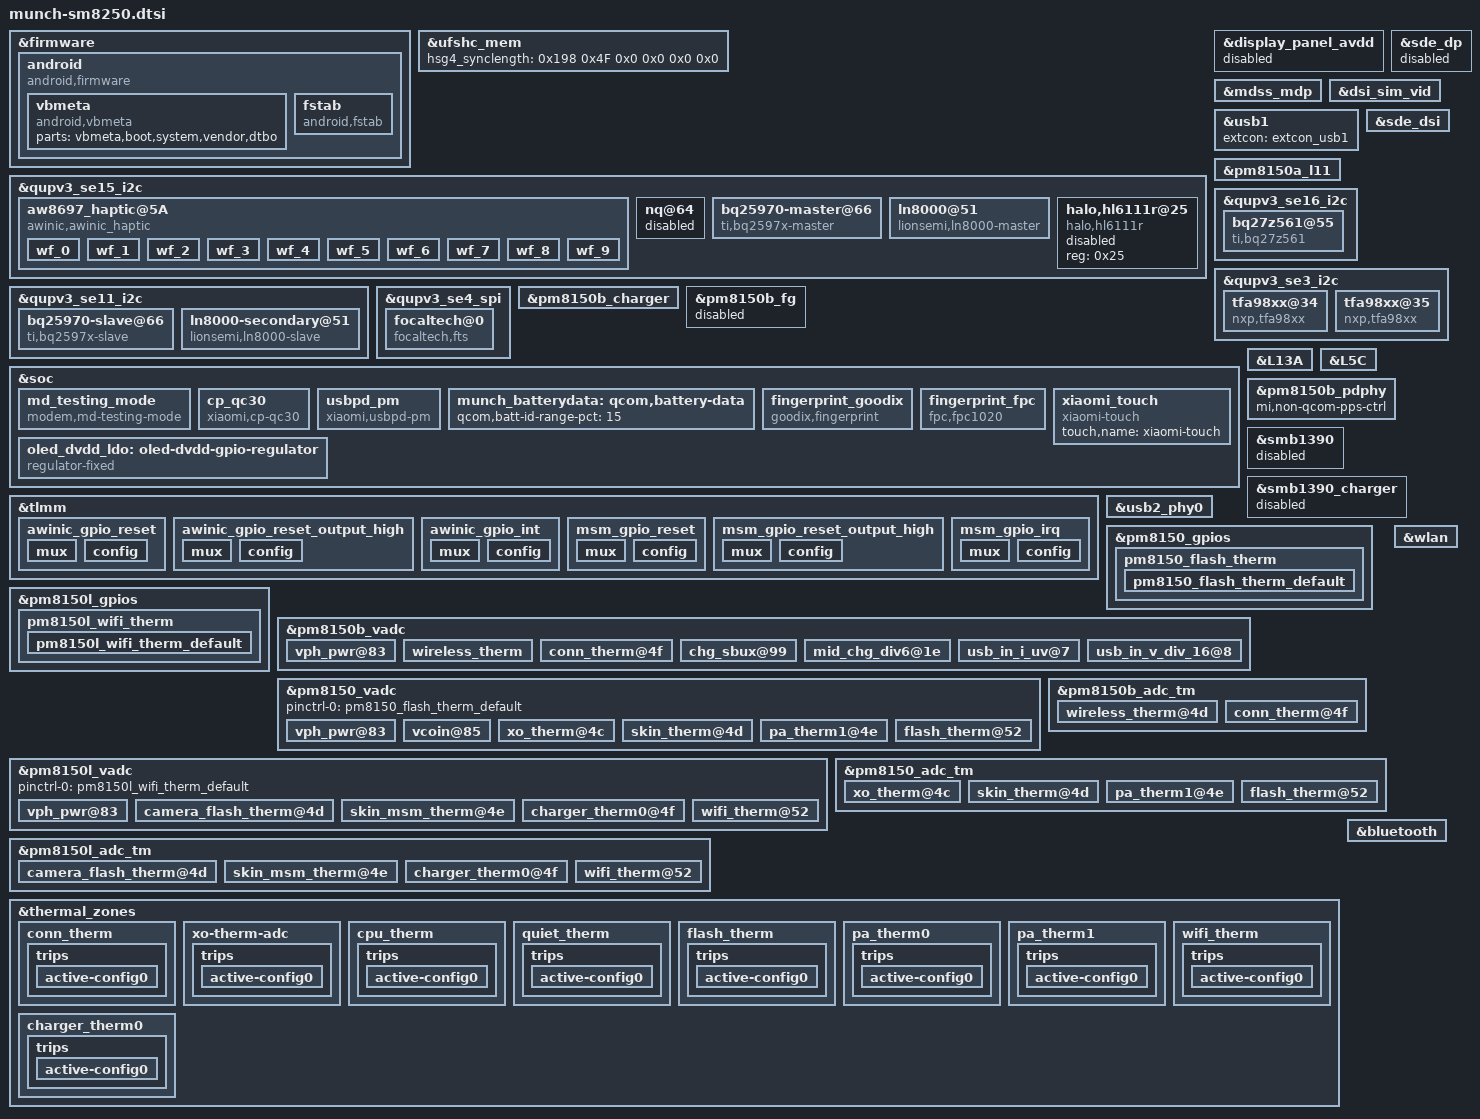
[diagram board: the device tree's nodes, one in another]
/*
this file is for attribution only of munch
And public attribution of xiaomi platforms(like L11R and so and)
*/

#include "munch-pinctrl.dtsi"
#include "xiaomi-sm8250-common.dtsi"
#include "munch-audio-overlay.dtsi"
&firmware {
	android {
		compatible = "android,firmware";
		vbmeta {
			compatible = "android,vbmeta";
			parts = "vbmeta,boot,system,vendor,dtbo";
		};

		fstab {
			compatible = "android,fstab";
		};
	};
};
&ufshc_mem {

	hsg4_synclength = /bits/ 16 <0x198 0x4F
				     0x0 0x0
				     0x0 0x0>;
};

&qupv3_se15_i2c {
	status = "ok";
	aw8697_haptic@5A {
		compatible = "awinic,awinic_haptic";
		reg = <0x5a>;
		reset-gpio = <&tlmm 130 0x00>;
		irq-gpio = <&tlmm 129 0x00>;
		pinctrl-names = "awinic_reset_reset","awinic_reset_active","awinic_interrupt_active";
		pinctrl-0 = <&awinic_gpio_reset>;
		pinctrl-1 = <&awinic_gpio_reset_output_high>;
		pinctrl-2 = <&awinic_gpio_int>;
		/*----------------------aw8697----------------------*/
		aw8697_vib_mode = < 0 >; /*mode:   RAM mode->0; CONT mode -> 1*/
		aw8697_vib_f0_pre = < 1300 >;
		aw8697_vib_f0_cali_percen = < 7 >;
		aw8697_vib_cont_drv_lev = < 60 >;
		aw8697_vib_cont_drv_lvl_ov = < 60 >;
		aw8697_vib_cont_td = < 0xef >;
		aw8697_vib_cont_zc_thr = < 0x08f8 >;  /*hq 0x08F8 */
		aw8697_vib_cont_num_brk = < 3 >;
		aw8697_vib_f0_coeff = < 260 >; /*Don't modify it 2.604167*/
		aw8697_vib_f0_trace_parameter = < 9 3 1 31 >;
		aw8697_vib_bemf_config = < 0 0x08 0x03 0xf8 >;
		aw8697_vib_sw_brake = < 0x2c >;
		aw8697_vib_tset = < 0x1a >;
		aw8697_vib_r_spare = < 0x68 >;
		aw8697_vib_bstdbg = < 0x30 0xeb 0xd4 0 0 0 >;
		aw8697_vib_trig_config = < 0 1 0 1 2
					   0 1 0 1 2
					   0 1 0 1 2 >;
		aw8697_vib_bst_vol_default = < 0x0e >;
		aw8697_vib_bst_vol_ram = < 0x0e >;
		aw8697_vib_bst_vol_rtp = < 0x0e >;
		/*----------------------aw8692x----------------------*/
		aw86927_vib_mode = < 0 >; /* mode: RAM mode->0; CONT mode->1 */
		aw86927_vib_f0_pre = < 1700 >;
		aw86927_vib_f0_cali_percen = < 7 >;
		aw86927_vib_cont_drv1_lvl = < 0x7F >;
		aw86927_vib_cont_drv2_lvl = < 0x36 >;
		aw86927_vib_cont_drv1_time = < 0x04 >;
		aw86927_vib_cont_drv2_time = < 0x06 >;
		aw86927_vib_cont_drv_width = < 0x6A >;
		aw86927_vib_cont_wait_num = < 0x06 >;
		aw86927_vib_cont_brk_time = < 0x08 >;
		aw86927_vib_cont_track_margin = < 0x0C >;
		aw86927_vib_brk_bst_md = < 0 >;
		aw86927_vib_cont_tset = < 0x06 >;
		aw86927_vib_cont_bemf_set = < 0x02 >;
		aw86927_vib_cont_bst_brk_gain = < 0x05 >;
		aw86927_vib_cont_brk_gain = < 0x08 >;
		aw86927_vib_d2s_gain = < 0x04 >;
		aw86927_vib_trig_config = < 0 0 0 1 0 2 0 0
					    0 0 0 1 0 2 0 0
					    0 0 0 1 0 2 0 0 >;
		aw86927_vib_bst_vol_default = < 0x58 >;
		aw86927_vib_bst_vol_ram = < 0x58 >;
		aw86927_vib_bst_vol_rtp = < 0x58 >;
		/*--------------------common--------------------*/
		vib_effect_id_boundary = < 10 >;
		vib_effect_max = < 197 >; /*vib_effect_max must bigger than vib_effect_id*/
		vib_rtp_time = < 20 20 20 20 20 20 20 20 20000 15000
				15000 20000 25000 15000 30000 25000 20000 20000 20000 20000
				20000 20000 20000 20000 20000 20000 20000 20000 20000 20000
				20000 20000 20000 20000 20000 20000 20000 20000 20000 20000
				20000 20000 20000 20000 20000 20000 20000 20000 20000 20000
				20000 20000 20000 20000 20000 20000 20000 20000 20000 20000
				20000 20000 20000 20000 20000 20000 20000 20000 20000 20000
				20000 20000 20000 20000 20000 20000 20000 20000 20000 20000
				20000 20000 20000 20000 20000 20000 20000 20000 20000 20000
				20000 20000 20000 20000 20000 20000 20000 20000 20000 20000
				20000 20000 20000 20000 20000 20000 20000 20000 20000 20000
				20000 20000 20000 20000 20000 20000 20000 20000 20000 20000
				20000 20000 20000 20000 20000 20000 20000 20000 20000 20000
				20000 20000 20000 20000 20000 20000 20000 20000 20000 20000
				20000 20000 20000 20000 20000 20000 20000 20000 20000 20000
				20000 20000 20000 20000 20000 20000 20000 20000 20000 20000
				20000 20000 20000 20000 20000 20000 20000 20000 20000 20000
				20000 20000 20000 20000 20000 >;
		status = "ok";
		wf_0 {
			/*CLICK*/
			qcom,effect-id = <0>;
			qcom,wf-vmax-mv = <3600>;
			qcom,wf-pattern = [3e 3e];
			qcom,wf-brake-pattern = [02 01 00 00];
			qcom,wf-play-rate-us = <20000>;
		};
		wf_1 {
			/*DOUBLE CLICK*/
			qcom,effect-id = <1>;
			qcom,wf-vmax-mv = <3600>;
			qcom,wf-pattern = [7e 3e];
			qcom,wf-brake-pattern = [03 01 00 00];
			qcom,wf-play-rate-us = <20000>;
		};
		wf_2 {
			/*TICK*/
			qcom,effect-id = <2>;
			qcom,wf-vmax-mv = <3600>;
			qcom,wf-pattern = [7e 3e];
			qcom,wf-brake-pattern = [02 01 00 00];
			qcom,wf-play-rate-us = <20000>;
		};
		wf_3 {
			/*THUD*/
			qcom,effect-id = <3>;
			qcom,wf-vmax-mv = <3600>;
			qcom,wf-pattern = [3e 3e];
			qcom,wf-brake-pattern = [02 01 00 00];
			qcom,wf-play-rate-us = <20000>;
		};
		wf_4 {
			/*POP*/
			qcom,effect-id = <4>;
			qcom,wf-vmax-mv = <3600>;
			qcom,wf-pattern = [3e 3e];
			qcom,wf-brake-pattern = [02 01 00 00];
			qcom,wf-play-rate-us = <28000>;
		};
		wf_5 {
			/*HEAVY CLICK*/
			qcom,effect-id = <5>;
			qcom,wf-vmax-mv = <3600>;
			qcom,wf-pattern = [7e 7e 7e];
			qcom,wf-brake-pattern = [03 03 01 00];
			qcom,wf-play-rate-us = <20000>;
		};
		wf_6 {
			/*id 6*/
			qcom,effect-id = <6>;
			qcom,wf-vmax-mv = <3600>;
			qcom,wf-pattern = [3e 3e];
			qcom,wf-brake-pattern = [02 01 00 00];
			qcom,wf-play-rate-us = <20000>;
		};
		wf_7 {
			/*id 7*/
			qcom,effect-id = <7>;
			qcom,wf-vmax-mv = <3600>;
			qcom,wf-pattern = [3e 3e];
			qcom,wf-brake-pattern = [02 01 00 00];
			qcom,wf-play-rate-us = <20000>;
		};
		wf_8 {
			/*id 8*/
			qcom,effect-id = <8>;
			qcom,wf-vmax-mv = <3600>;
			qcom,wf-pattern = [3e 3e];
			qcom,wf-brake-pattern = [02 01 00 00];
			qcom,wf-play-rate-us = <20000>;
		};
		wf_9 {
			/*id 9*/
			qcom,effect-id = <9>;
			qcom,wf-vmax-mv = <3600>;
			qcom,wf-pattern = [3e 3e];
			qcom,wf-brake-pattern = [02 01 00 00];
			qcom,wf-play-rate-us = <20000>;
		};
	};
	nq@64 {
		status = "disabled";
	};
};

&display_panel_avdd {
	status = "disabled";
};

&sde_dp {
	status = "disabled";
};

&mdss_mdp {
	connectors = <&sde_wb &sde_dsi &sde_dsi1 &sde_rscc>;
};

&dsi_sim_vid {
	qcom,panel-supply-entries = <&dsi_panel_pwr_supply_vci>;
	qcom,platform-reset-gpio = <&tlmm 12 0>;
};

&usb1 {
        extcon = <&extcon_usb1>;
};

/*display team xiexiaobo add*/
&dsi_sim_vid {
	qcom,mdss-dsi-bl-min-level = <1>;
	qcom,mdss-dsi-bl-max-level = <2047>;
	qcom,mdss-brightness-max-level = <2047>;
	qcom,mdss-brightness-init-level = <536>;
};

&sde_dsi {
	/delete-property/ vdd-supply;
	/delete-property/ avdd-supply;
	qcom,dsi-default-panel = <&dsi_sim_vid>;
	vci-supply = <&pm8150a_l11>;
	/delete-property/ dvdd-supply;
};

&pm8150a_l11 {
	qcom,init-voltage = <3000000>;
	regulator-min-microvolt = <3000000>;
	regulator-max-microvolt = <3000000>;
};
/*display team xiexiaobo end*/
&qupv3_se15_i2c {
	#address-cells = <1>;
	#size-cells = <0>;
	status = "ok";

	bq25970-master@66 {
		compatible = "ti,bq2597x-master";
		reg = <0x66>;
		interrupt-parent = <&tlmm>;
		interrupts = <68 0x2002>;
		pinctrl-names = "default";
		pinctrl-0 = <&bq2597x_master_int_default>;

		/*ti,bq2597x,bat-ovp-disable;*/
		ti,bq2597x,bat-ovp-alarm-disable;
		ti,bq2597x,bat-ocp-disable;
		ti,bq2597x,bat-ocp-alarm-disable;
		ti,bq2597x,bat-ucp-alarm-disable;
		ti,bq2597x,bat-ucp-disable;

		ti,bq2597x,bus-ovp-alarm-disable;
		ti,bq2597x,bus-ocp-disable;
		ti,bq2597x,bus-ocp-alarm-disable;
		ti,bq2597x,bat-therm-disable;
		ti,bq2597x,bus-therm-disable;
		ti,bq2597x,die-therm-disable;

		ti,bq2597x,bat-ovp-threshold = <4550>;
		ti,bq2597x,bat-ovp-alarm-threshold = <4525>;
		//ti,bq2597x,bat-ocp-threshold = <8000>;
		//ti,bq2597x,bat-ocp-alarm-threshold = <7500>;

		ti,bq2597x,bus-ovp-threshold = <12000>;
		ti,bq2597x,bus-ovp-alarm-threshold = <11000>;
		ti,bq2597x,bus-ocp-threshold = <3750>;
		ti,bq2597x,bus-ocp-alarm-threshold = <3500>;

		//ti,bq2597x,bat-ucp-alarm-threshold = <2000>;

		ti,bq2597x,bat-therm-threshold = <0x15>;/*4.1%*/
		ti,bq2597x,bus-therm-threshold = <0x15>;/*4.1%*/
		ti,bq2597x,die-therm-threshold = <145>;

		ti,bq2597x,ac-ovp-threshold = <14>;
		//ti,bq2597x,sense-resistor-mohm = <2>;

		sc8551,ac-ovp-threshold = <14>;
	};

	ln8000@51 {
		compatible = "lionsemi,ln8000-master";
		reg = <0x51>;
		/* bank <bit-idx> <flags: active-low> */
		//irq-gpios = <&tlmm 55 0x2002>;
		pinctrl-names = "bq2597x_master_irq";
		pinctrl-0 = <&bq2597x_master_int_default &bq2597x_master_int_suspend>;

		charger_name = "tertiary_chg";

		interrupt-parent = <&tlmm>;
		interrupts = <68 0x2002>;

		//interrupt-parent = <&tlmm>;
		//interrupts = <55 0x2002>;
		//pinctrl-names = "default";
		//pinctrl-0 = <&bq2597x_int_default &bq2597x_int_suspend>;
		//ln8000_charger,irq_index = <296>;

		ln8000_charger,standalone-mode-master;
		/* device configuration */
		ln8000_charger,bat-ovp-threshold = <4710>;
		ln8000_charger,bat-ovp-alarm-threshold = <4675>;
		ln8000_charger,bus-ovp-threshold = <13000>;
		ln8000_charger,bus-ovp-alarm-threshold = <11000>;
		ln8000_charger,bus-ocp-threshold = <3750>;
		ln8000_charger,bus-ocp-alarm-threshold = <3500>;
		ln8000_charger,ntc-alarm-cfg  = <226>;
		/* protection enable/disable flags
		 *   vbat-ovp-disable
		 *   vbat-reg-disable
		 *   iin-ocp-disable
		 *   iin-reg-disable
		 *   tbus-mon-disable
		 *   tbat-mon-disable
		 *   tdie-prot-disable
		 *   tdie-reg-disable
		 *   revcurr-prot-disable
		 */
		ln8000_charger,tdie-prot-disable;
		ln8000_charger,tbus-mon-disable;
		ln8000_charger,tbat-mon-disable;
		ln8000_charger,iin-ocp-disable;
		ln8000_charger,iin-reg-disable;
		ln8000_charger,tdie-reg-disable;
		ln8000_charger,vbat-reg-disable;
	};



	halo,hl6111r@25 {
		compatible = "halo,hl6111r";
		reg = <0x25>;
		status = "disabled";
	};
};
&qupv3_se16_i2c {
	#address-cells = <1>;
	#size-cells = <0>;
	status = "ok";

	bq27z561@55 {
		compatible = "ti,bq27z561";
		reg = <0x55>;
		bq,ignore-digest-debug;
		bq,charge-full-design = <4500000>;
		bq,recharge-voltage   = <4380>;
		bq,shutdown-delay-enable;
		bq,soc_decimal_rate = <
			0  38
			10 35
			20 33
			30 33
			40 33
			50 33
			60 33
			70 30
			80 25
			90 20
			95 10 >;
		bq,cold_thermal_seq = <
			1      0  100 1700
			2  (-300)   0 1000 >;
	};

};



&qupv3_se3_i2c {
	status = "ok";
	/* TOP Speaker */
	tfa98xx@34 {
		compatible = "nxp,tfa98xx";
		reset-gpio = <&tlmm 114 0>;
		irq-gpio = <&tlmm 113 0>;
		spk-sw-gpio = <&tlmm 127 0>;
		interrupt-parent = <&tlmm>;
		interrupts = <113 0>;
		interrupt-names = "smartpa_irq";
		pinctrl-names = "default", "sleep";
		pinctrl-0 = <&smartpa_top_int_active &smartpa_enable_top_active/* &spk_sw_active*/>;
		pinctrl-1 = <&smartpa_top_int_suspend &smartpa_enable_top_suspend/* &spk_sw_inactive*/>;
		reg = <0x34>;
		status = "ok";
	};
        /* Botton Speaker */
	tfa98xx@35 {
		compatible = "nxp,tfa98xx";
		reset-gpio = <&tlmm 140 0>;
		irq-gpio = <&tlmm 112 0>;
		//spk-sw-gpio = <&tlmm 110 0>;
		interrupt-parent = <&tlmm>;
		interrupts = <112 0>;
		interrupt-names = "smartpa_irq";
		pinctrl-names = "default", "sleep";
		pinctrl-0 = <&smartpa_bot_int_active &smartpa_enable_bot_active>;
		pinctrl-1 = <&smartpa_bot_int_suspend &smartpa_enable_bot_suspend>;
		reg = <0x35>;
		status = "ok";
	};
};

&qupv3_se11_i2c {
	#address-cells = <1>;
	#size-cells = <0>;
	status = "ok";
	bq25970-slave@66 {
		compatible = "ti,bq2597x-slave";
		reg = <0x66>;
		/*
		interrupt-parent = <&tlmm>;
		interrupts = <1 2>;
		pinctrl-names = "default";
		pinctrl-0 = <&bq2597x_int_default>;
		*/

		/*ti,bq2597x,bat-ovp-disable;*/
		ti,bq2597x,bat-ovp-alarm-disable;
		ti,bq2597x,bat-ocp-disable;
		ti,bq2597x,bat-ocp-alarm-disable;
		ti,bq2597x,bat-ucp-alarm-disable;

		ti,bq2597x,bat-ucp-disable;

		ti,bq2597x,bus-ovp-alarm-disable;
		ti,bq2597x,bus-ocp-disable;
		ti,bq2597x,bus-ocp-alarm-disable;
		ti,bq2597x,bat-therm-disable;
		ti,bq2597x,bus-therm-disable;
		ti,bq2597x,die-therm-disable;

		ti,bq2597x,bat-ovp-threshold = <4550>;
		ti,bq2597x,bat-ovp-alarm-threshold = <4525>;
		//ti,bq2597x,bat-ocp-threshold = <8000>;
		//ti,bq2597x,bat-ocp-alarm-threshold = <7500>;

		ti,bq2597x,bus-ovp-threshold = <12000>;
		ti,bq2597x,bus-ovp-alarm-threshold = <11000>;
		ti,bq2597x,bus-ocp-threshold = <3500>;
		ti,bq2597x,bus-ocp-alarm-threshold = <3000>;

		//ti,bq2597x,bat-ucp-alarm-threshold = <2000>;

		ti,bq2597x,bat-therm-threshold = <0x15>;/*4.1%*/
		ti,bq2597x,bus-therm-threshold = <0x15>;/*4.1%*/
		ti,bq2597x,die-therm-threshold = <125>;

		ti,bq2597x,ac-ovp-threshold = <14>;
		//ti,bq2597x,sense-resistor-mohm = <2>;

		sc8551,ac-ovp-threshold = <13>;
	};

	ln8000-secondary@51 {
		compatible = "lionsemi,ln8000-slave";
		reg = <0x51>;
		//pinctrl-names = "bq2597x_slave_irq";
		//pinctrl-0 = <&bq2597x_slave_int_default &bq2597x_slave_int_suspend>;

		charger_name = "quaternary_chg";
		/* bank <bit-idx> <flags: active-low> */
		//irq-gpios = <&tlmm 55 0x2002>;
		interrupt-parent = <&tlmm>;
		interrupts = <64 0x2002>;

		//interrupt-parent = <&tlmm>;
		//interrupts = <55 0x2002>;
		//pinctrl-names = "default";
		//pinctrl-0 = <&bq2597x_int_default &bq2597x_int_suspend>;
		//ln8000_charger,irq_index = <296>;

		ln8000_charger,standalone-mode-slave;
		/* device configuration */
		ln8000_charger,bat-ovp-threshold = <4710>;
		ln8000_charger,bat-ovp-alarm-threshold = <4675>;
		ln8000_charger,bus-ovp-threshold = <13000>;
		ln8000_charger,bus-ovp-alarm-threshold = <11000>;
		ln8000_charger,bus-ocp-threshold = <3750>;
		ln8000_charger,bus-ocp-alarm-threshold = <3500>;
		ln8000_charger,ntc-alarm-cfg  = <226>;
		/* protection enable/disable flags
		 *   vbat-ovp-disable
		 *   vbat-reg-disable
		 *   iin-ocp-disable
		 *   iin-reg-disable
		 *   tbus-mon-disable
		 *   tbat-mon-disable
		 *   tdie-prot-disable
		 *   tdie-reg-disable
		 *   revcurr-prot-disable
		 */
		ln8000_charger,tdie-prot-disable;
		ln8000_charger,tbus-mon-disable;
		ln8000_charger,tbat-mon-disable;
		ln8000_charger,iin-ocp-disable;
		ln8000_charger,iin-reg-disable;
		ln8000_charger,tdie-reg-disable;
		ln8000_charger,vbat-reg-disable;
	};
};

&qupv3_se4_spi {
	status = "ok";
	focaltech@0 {
		status = "ok";
		compatible = "focaltech,fts";
		reg = <0x0>;
		spi-max-frequency = <6000000>;
		interrupt-parent = <&tlmm>;
		interrupts = <39 0x2008>;
		pinctrl-names = "pmx_ts_active", "pmx_ts_suspend", "pmx_ts_release";
		pinctrl-0 = <&ts_active>;
		pinctrl-1 = <&ts_int_suspend &ts_reset_suspend>;
		pinctrl-2 = <&pmx_ts_release>;
		vdd-supply = <&L10C>;
		vcc_i2c-supply = <&L1C>;
		focaltech,reset-gpio = <&tlmm 33 0x00>;
		focaltech,irq-gpio = <&tlmm 39 0x2008>;
		focaltech,max-touch-number = <10>;
		focaltech,display-coords = <0 0 10800 24000>;
		focaltech,open-min = <3000>;
		focaltech,touch-range-array = <1 5 10 15 20>;
		focaltech,touch-def-array = <3 3 3 3>;
		focaltech,touch-expert-array = <10 10 10 10
						20 20 15 10
						20 20 20 10>;
	};
};

&pm8150b_charger {
	status = "ok";
	qcom,sec-charger-config = <0>;
	qcom,usb-icl-ua = <6200000>;
	qcom,fcc-max-ua = <12400000>;
	qcom,fv-max-uv = <4480000>;
	qcom,non-fcc-fv-max-uv = <4450000>;
	qcom,dc-icl-ua = <1000000>;
	qcom,auto-recharge-vbat-mv = <4380000>;
	qcom,chg-term-src = <1>;
	qcom,chg-term-current-ma = <(-200)>;
	qcom,step-charging-enable;
	qcom,sw-jeita-enable;
	qcom,chg-warm-th= <480>;
	qcom,chg-cool-th= <150>;
	//qcom,suspend-input-on-debug-batt;
	pinctrl-names = "default", "smb5_active", "smb5_suspend";
	pinctrl-0 = <&vbus_disable_suspend>;
	qcom,usbpd-phandle = <&pm8150b_pdphy>;
	qcom,battery-data = <&munch_batterydata>;
	//mi,fcc-batt-unverify-ua = <2000000>;
	mi,support-ffc;
	qcom,lpd-disable;
	mi,use-bq-pump;
	qcom,support-ext-fg;
	mi,support-qc3p5-without-smb;
	qcom,disable-suspend-on-collapse;
	qcom,distinguish-qc-class-ab;
	qcom,support-conn-therm;
	vbus-disable-gpio = <&tlmm 46 GPIO_ACTIVE_HIGH>;
	pinctrl-names = "default", "vbus_disable_active", "vbus_disable_suspend";
	pinctrl-0 = <&vbus_disable_suspend>;
	pinctrl-1 = <&vbus_disable_active>;
	pinctrl-2 = <&vbus_disable_suspend>;

	io-channels = <&pm8150b_vadc ADC_USB_IN_V_16>,
			<&pm8150b_vadc ADC_MID_CHG_DIV6>,
			<&pm8150b_vadc ADC_USB_IN_I>,
			<&pm8150b_vadc ADC_SBUx>,
			<&pm8150b_vadc ADC_VPH_PWR>,
			<&pm8150b_vadc ADC_AMUX_THM3_PU2>,
			<&pm8150b_vadc ADC_CHG_TEMP>;
	io-channel-names = "usb_in_voltage",
			"mid_voltage",
			"usb_in_current",
			"sbux_res",
			"vph_voltage",
			"conn_temp",
			"chg_temp";
	qcom,thermal-mitigation = <3000000 2800000 2600000 2400000 2200000 2100000 2000000
				   1800000 1600000 1500000 1400000 1200000 1000000 900000
				   800000 500000>;
	qcom,thermal-mitigation-icl
				= <2800000 2700000 2600000 2400000 2200000 2100000 2000000
				   1800000 1600000 1500000 1400000 1300000 1200000 1100000
				   950000 750000>;
	qcom,thermal-mitigation-dcp
				= <1800000 1800000 1800000 1800000 1800000 1800000 1800000
				   1800000 1800000 1700000 1600000 1400000 1200000 1100000
				   1100000 1000000>;
	qcom,thermal-mitigation-qc2
				= <1500000 1500000 1500000 1500000 1450000 1400000 1350000
				   1300000 1150000 1100000 1000000 900000 850000 750000
				   650000 500000>;
	qcom,thermal-fcc-qc3-normal
				= <3200000 3000000 2800000 2600000 2500000 2400000 2300000
				   2200000 2100000 1800000 1600000 1400000 1200000 1000000
				   750000 750000>;
	qcom,thermal-fcc-qc3-cp
				= <4800000 4600000 4400000 4200000 4000000 3800000 3600000
				   3400000 3000000 2600000 2400000 2200000 2000000 1300000
				   1000000 700000>;
	qcom,thermal-fcc-qc3-classb-cp
				= <5100000 4700000 4300000 4000000 3600000 3500000 3400000
				   3400000 3400000 3200000 2500000 2200000 2000000 1300000
				   1000000 700000>;
	qcom,thermal-mitigation-pd-base
				= <3000000 2800000 2600000 2400000 2200000 2000000 1800000
				   1600000 1600000 1400000 1200000 1100000 1050000 1000000
				   950000 500000>;
	qcom,thermal-fcc-pps-bq
				= <12400000 11000000 10000000 8800000 8000000 7500000 7000000
				   6500000 6000000 5500000 5000000 4000000 2650000 2000000
				   1000000 500000>;
};

&pm8150b_fg {
	status = "disabled";
};

&soc {
        md_testing_mode {
		compatible = "modem,md-testing-mode";
		status-gpio = <&tlmm 14 0x00>,
                      <&tlmm 15 0x00>;
		debounce-time = <30>;
		pinctrl-names = "default";
		pinctrl-0 = <&ant2_ctrl_irq &ant5_ctrl_irq>;
	};

	cp_qc30 {
		compatible = "xiaomi,cp-qc30";
		status = "ok";
		mi,qc3-bat-volt-max = <4480>;
		mi,qc3-bat-curr-max = <3600>;
		mi,qc3-bus-volt-max = <12000>;
		mi,qc3-bus-curr-max = <2100>;
		mi,qc3-battery-warm-th = <480>;
		mi,cp-sec-enable;
		mi,support-qc3p5-without-smb;
	};

	usbpd_pm {
		compatible = "xiaomi,usbpd-pm";
		status = "ok";
		mi,pd-bat-volt-max = <4480>;
		mi,pd-bat-curr-max = <12400>;
		mi,pd-bus-volt-max = <12000>;
		mi,pd-bus-curr-max = <6200>;
		mi,pd-non-ffc-bat-volt-max = <4450>;
		mi,pd-bus-curr-compensate  = <0>;
		mi,step-charge-high-vol-curr-max = <4400>;
		mi,cell-vol-high-threshold-mv = <4500>;
		mi,cell-vol-max-threshold-mv = <4480>;
		mi,pd-battery-warm-th = <480>;
		mi,cp-sec-enable;
	};

/*
	maxim_ds28e16: maxim_ds28e16 {
		compatible = "maxim,ds28e16";
		label = "max_ds28e16";
		maxim,version = <1>;
		status = "ok";
	};
*/
	munch_batterydata: qcom,battery-data {
		qcom,batt-id-range-pct = <15>;
		#include "jeita-step-cfg-munch.dtsi"
	};

	fingerprint_goodix {
		compatible = "goodix,fingerprint";
		goodix,gpio-reset = <&tlmm 24 0x0>;
		goodix,gpio-irq = <&tlmm 23 0x0>;
		fp_vdd_vreg-supply = <&L13A>;
		status = "ok";
	};

	fingerprint_fpc {
		status = "ok";
		compatible = "fpc,fpc1020";
		interrupt-parent = <&tlmm>;
		interrupts = <23 0x0>;
		fpc,gpio_rst    = <&tlmm 24 0x0>;
		fpc,gpio_irq    = <&tlmm 23 0x0>;
		fp_vdd_vreg-supply = <&L5C>;
		pinctrl-names = "fpc1020_reset_reset",
			"fpc1020_reset_active",
			"fpc1020_irq_active";

		pinctrl-0 = <&msm_gpio_reset>;
		pinctrl-1 = <&msm_gpio_reset_output_high>;
		pinctrl-2 = <&msm_gpio_irq>;

	};

/*
	fingerprint_3P0_VREG: fingerprint_3P0_VREG {
		compatible = "regulator-fixed";
		regulator-name = "fingerprint_3P0_VREG";
		startup-delay-us = <4000>;
		enable-active-high;
		gpio = <&tlmm 10 0>;
		regulator-always-on;
	};
*/

	xiaomi_touch {
		compatible = "xiaomi-touch";
		status = "ok";
		touch,name = "xiaomi-touch";
	};

	oled_dvdd_ldo: oled-dvdd-gpio-regulator {
		compatible = "regulator-fixed";
		regulator-name = "oled_dvdd_ldo";
		regulator-min-microvolt = <1200000>;
		regulator-max-microvolt = <1200000>;
		regulator-enable-ramp-delay = <135>;
		enable-active-high;
		gpio = <&tlmm 69 0>;
		pinctrl-names = "default";
		pinctrl-0 = <&oled_dvdd_ldo_en>;
		vin-supply = <&pm8150a_bob>;
	};
};


&tlmm {

/* AW8697_RESET_N */
        awinic_gpio_reset: awinic_gpio_reset {
                mux {
                         pins = "gpio130";
                         function = "gpio";
                };

                config {
                        pins = "gpio130";
                        drive-strength = <2>;
                        bias-disable;
                        output-low;
                };
        };
        /* AW8697_RESET_N, state device active*/
        awinic_gpio_reset_output_high: awinic_gpio_reset_output_high {
                mux {
                        pins = "gpio130";
                        function = "gpio";
                };

                config {
                        pins = "gpio130";
                        drive-strength = <2>;
                        bias-disable;
                        output-high;
                };
        };

        /* AW8697_INTERRUPT_N */
        awinic_gpio_int: awinic_gpio_int {
                mux {
                        pins = "gpio129";
                        function = "gpio";
                };

                config {
                        pins = "gpio129";
                        drive-strength = <2>;
                        bias-pull-up;
                        input-enable;
                };
        };
};

/* fingerprint start */
&L13A {
	regulator-min-microvolt = <3000000>;
	regulator-max-microvolt = <3000000>;
	qcom,init-voltage = <3000000>;
};
&L5C {
	regulator-min-microvolt = <1800000>;
	regulator-max-microvolt = <1800000>;
	qcom,init-voltage = <1800000>;
};
/* fingerprint end */

&tlmm {
		/* FP_RESET_N */
	msm_gpio_reset: msm_gpio_reset {
		mux {
			pins = "gpio24";
			function = "gpio";
		};
		config {
			pins = "gpio24";
			drive-strength = <2>;
			bias-disable;
			output-low;
		};
	};
		/* FP_RESET_N, state device active*/
	msm_gpio_reset_output_high: msm_gpio_reset_output_high {
		mux {
			pins = "gpio24";
			function = "gpio";
		};
		config {
			pins = "gpio24";
			drive-strength = <2>;
			bias-disable;
			output-high;
		};
	};
		/* FP_INT_N */
	msm_gpio_irq: msm_gpio_irq {
		mux {
			pins = "gpio23";
			function = "gpio";
		};
		config {
			pins = "gpio23";
			drive-strength = <2>;
			bias-pull-down;
		};
	};
};


&pm8150b_pdphy {
	mi,non-qcom-pps-ctrl;
};

&smb1390 {
	status = "disabled";
};

&smb1390_charger {
	status = "disabled";
};

&usb2_phy0 {
	qcom,param-override-seq =
		<0xE7 0x6C
		 0xC9 0x70
		 0x21 0x74>;
	qcom,global-param-override-seq =
		<0xE5 0x6C
		 0x79 0x70
		 0x21 0x74>;
};

&pm8150_gpios {
	pm8150_flash_therm {
		pm8150_flash_therm_default: pm8150_flash_therm_default {
			pins = "gpio3";
			bias-high-impedance;
		};
	};
};

&pm8150l_gpios {
	pm8150l_wifi_therm {
		pm8150l_wifi_therm_default: pm8150l_wifi_therm_default {
			pins = "gpio5";
			bias-high-impedance;
		};
	};
};

&pm8150b_vadc {
	#address-cells = <1>;
	#size-cells = <0>;

	vph_pwr@83 {
		reg = <ADC_VPH_PWR>;
		label = "vph_pwr";
		qcom,pre-scaling = <1 3>;
	};

	wireless_therm {
		reg = <ADC_AMUX_THM1_PU2>;
		label = "wireless_therm";
		qcom,ratiometric;
		qcom,hw-settle-time = <200>;
		qcom,pre-scaling = <1 1>;
	};

	conn_therm@4f {
		reg = <ADC_AMUX_THM3_PU2>;
		label = "conn_therm";
		qcom,ratiometric;
		qcom,hw-settle-time = <200>;
		qcom,pre-scaling = <1 1>;
	};

	chg_sbux@99 {
		reg = <ADC_SBUx>;
		label = "chg_sbux";
		qcom,pre-scaling = <1 3>;
	};

	mid_chg_div6@1e {
		reg = <ADC_MID_CHG_DIV6>;
		label = "chg_mid";
		qcom,pre-scaling = <1 6>;
	};

	usb_in_i_uv@7 {
		reg = <ADC_USB_IN_I>;
		label = "usb_in_i_uv";
		qcom,pre-scaling = <1 1>;
	};

	usb_in_v_div_16@8 {
		reg = <ADC_USB_IN_V_16>;
		label = "usb_in_v_div_16";
		qcom,pre-scaling = <1 16>;
	};

/*	charger_therm0@4a {
		reg = <ADC_BAT_THERM_PU2>;
		label = "charger_therm0";
		qcom,ratiometric;
		qcom,hw-settle-time = <200>;
		qcom,pre-scaling = <1 1>;
	};
*/
};

&pm8150_vadc {
	#address-cells = <1>;
	#size-cells = <0>;
	pinctrl-names = "default";
	pinctrl-0 = <&pm8150_flash_therm_default>;

	vph_pwr@83 {
		reg = <ADC_VPH_PWR>;
		label = "vph_pwr";
		qcom,pre-scaling = <1 3>;
	};

	vcoin@85 {
		reg = <ADC_VCOIN>;
		label = "vcoin";
		qcom,pre-scaling = <1 3>;
	};

	xo_therm@4c {
		reg = <ADC_XO_THERM_PU2>;
		label = "xo_therm";
		qcom,ratiometric;
		qcom,hw-settle-time = <200>;
		qcom,pre-scaling = <1 1>;
	};

	skin_therm@4d {
		reg = <ADC_AMUX_THM1_PU2>;
		label = "skin_therm";
		qcom,ratiometric;
		qcom,hw-settle-time = <200>;
		qcom,pre-scaling = <1 1>;
	};

	pa_therm1@4e {
		reg = <ADC_AMUX_THM2_PU2>;
		label = "pa_therm1";
		qcom,ratiometric;
		qcom,hw-settle-time = <200>;
		qcom,pre-scaling = <1 1>;
	};

	flash_therm@52 {
		reg = <ADC_GPIO1_PU2>;
		label = "flash_therm";
		qcom,ratiometric;
		qcom,hw-settle-time = <200>;
		qcom,pre-scaling = <1 1>;
	};
};

&pm8150l_vadc {
	#address-cells = <1>;
	#size-cells = <0>;
	pinctrl-0 = <&pm8150l_wifi_therm_default>;

	vph_pwr@83 {
		reg = <ADC_VPH_PWR>;
		label = "vph_pwr";
		qcom,pre-scaling = <1 3>;
	};

	camera_flash_therm@4d {
		reg = <ADC_AMUX_THM1_PU2>;
		label = "camera_flash_therm";
		qcom,ratiometric;
		qcom,hw-settle-time = <200>;
		qcom,pre-scaling = <1 1>;
	};

	skin_msm_therm@4e {
		reg = <ADC_AMUX_THM2_PU2>;
		label = "skin_msm_therm";
		qcom,ratiometric;
		qcom,hw-settle-time = <200>;
		qcom,pre-scaling = <1 1>;
	};

	charger_therm0@4f {
		reg = <ADC_AMUX_THM3_PU2>;
		label = "charger_therm0";
		qcom,ratiometric;
		qcom,hw-settle-time = <200>;
		qcom,pre-scaling = <1 1>;
	};

	wifi_therm@52 {
		reg = <ADC_GPIO1_PU2>;
		label = "wifi_therm";
		qcom,ratiometric;
		qcom,hw-settle-time = <200>;
		qcom,pre-scaling = <1 1>;
	};
};

&pm8150b_adc_tm {
	#address-cells = <1>;
	#size-cells = <0>;

	io-channels = <&pm8150b_vadc ADC_AMUX_THM1_PU2>,
			<&pm8150b_vadc ADC_AMUX_THM3_PU2>;

	wireless_therm@4d {
		reg = <ADC_AMUX_THM1_PU2>;
		qcom,ratiometric;
		qcom,hw-settle-time = <200>;
	};

	conn_therm@4f {
		reg = <ADC_AMUX_THM3_PU2>;
		qcom,ratiometric;
		qcom,hw-settle-time = <200>;
	};

/*	charger_therm0@4a {
		reg = <ADC_BAT_THERM_PU2>;
		qcom,ratiometric;
		qcom,hw-settle-time = <200>;
	};
*/
};

&pm8150_adc_tm {
	#address-cells = <1>;
	#size-cells = <0>;

	io-channels = <&pm8150_vadc ADC_XO_THERM_PU2>,
			<&pm8150_vadc ADC_AMUX_THM1_PU2>,
			<&pm8150_vadc ADC_AMUX_THM2_PU2>,
			<&pm8150_vadc ADC_GPIO1_PU2>;

	xo_therm@4c {
		reg = <ADC_XO_THERM_PU2>;
		qcom,ratiometric;
		qcom,hw-settle-time = <200>;
	};

	skin_therm@4d {
		reg = <ADC_AMUX_THM1_PU2>;
		qcom,ratiometric;
		qcom,hw-settle-time = <200>;
	};

	pa_therm1@4e {
		reg = <ADC_AMUX_THM2_PU2>;
		qcom,ratiometric;
		qcom,hw-settle-time = <200>;
	};

	flash_therm@52 {
		reg = <ADC_GPIO1_PU2>;
		qcom,ratiometric;
		qcom,hw-settle-time = <200>;
	};
};

&pm8150l_adc_tm {
	#address-cells = <1>;
	#size-cells = <0>;

	io-channels = <&pm8150l_vadc ADC_AMUX_THM1_PU2>,
			<&pm8150l_vadc ADC_AMUX_THM2_PU2>,
			<&pm8150l_vadc ADC_AMUX_THM3_PU2>,
			<&pm8150l_vadc ADC_GPIO1_PU2>;

	camera_flash_therm@4d {
		reg = <ADC_AMUX_THM1_PU2>;
		qcom,ratiometric;
		qcom,hw-settle-time = <200>;
	};

	skin_msm_therm@4e {
		reg = <ADC_AMUX_THM2_PU2>;
		qcom,ratiometric;
		qcom,hw-settle-time = <200>;
	};

	charger_therm0@4f {
		reg = <ADC_AMUX_THM3_PU2>;
		qcom,ratiometric;
		qcom,hw-settle-time = <200>;
	};

	wifi_therm@52 {
		reg = <ADC_GPIO1_PU2>;
		qcom,ratiometric;
		qcom,hw-settle-time = <200>;
	};
};

&thermal_zones {
/*	wireless_therm {//place close to wireless charge RX
		polling-delay-passive = <0>;
		polling-delay = <0>;
		thermal-governor = "user_space";
		thermal-sensors = <&pm8150b_adc_tm ADC_AMUX_THM1_PU2>;
		trips {
			active-config0 {
				temperature = <125000>;
				hysteresis = <1000>;
				type = "passive";
			};
		};
	};
*/

	conn_therm {//place close to type-c connector
		polling-delay-passive = <0>;
		polling-delay = <0>;
		thermal-governor = "user_space";
		thermal-sensors = <&pm8150b_adc_tm ADC_AMUX_THM3_PU2>;
		wake-capable-sensor;
		trips {
			active-config0 {
				temperature = <125000>;
				hysteresis = <1000>;
				type = "passive";
			};
		};
	};

	xo-therm-adc {
		polling-delay-passive = <0>;
		polling-delay = <0>;
		thermal-governor = "user_space";
		thermal-sensors = <&pm8150_adc_tm ADC_XO_THERM_PU2>;
		wake-capable-sensor;
		trips {
			active-config0 {
				temperature = <125000>;
				hysteresis = <1000>;
				type = "passive";
			};
		};
	};

	cpu_therm {//place close to sm8250
		polling-delay-passive = <0>;
		polling-delay = <0>;
		thermal-governor = "user_space";
		thermal-sensors = <&pm8150_adc_tm ADC_AMUX_THM1_PU2>;
		wake-capable-sensor;
		trips {
			active-config0 {
				temperature = <125000>;
				hysteresis = <1000>;
				type = "passive";
			};
		};
	};

	quiet_therm {//place close to a cool place
		polling-delay-passive = <0>;
		polling-delay = <0>;
		thermal-governor = "user_space";
		thermal-sensors = <&pm8150_adc_tm ADC_AMUX_THM2_PU2>;
		wake-capable-sensor;
		trips {
			active-config0 {
				temperature = <125000>;
				hysteresis = <1000>;
				type = "passive";
			};
		};
	};

	flash_therm {//place close to flash fpc
		polling-delay-passive = <0>;
		polling-delay = <0>;
		thermal-governor = "user_space";
		thermal-sensors = <&pm8150_adc_tm ADC_GPIO1_PU2>;
		wake-capable-sensor;
		trips {
			active-config0 {
				temperature = <125000>;
				hysteresis = <1000>;
				type = "passive";
			};
		};
	};

	pa_therm0 {//place close to pa0
		polling-delay-passive = <0>;
		polling-delay = <0>;
		thermal-governor = "user_space";
		thermal-sensors = <&pm8150l_adc_tm ADC_AMUX_THM1_PU2>;
		wake-capable-sensor;
		trips {
			active-config0 {
				temperature = <125000>;
				hysteresis = <1000>;
				type = "passive";
			};
		};
	};

	pa_therm1 {//place close to pa1
		polling-delay-passive = <0>;
		polling-delay = <0>;
		thermal-governor = "user_space";
		thermal-sensors = <&pm8150l_adc_tm ADC_AMUX_THM2_PU2>;
		wake-capable-sensor;
		trips {
			active-config0 {
				temperature = <125000>;
				hysteresis = <1000>;
				type = "passive";
			};
		};
	};

	wifi_therm {//place close to wifi
		polling-delay-passive = <0>;
		polling-delay = <0>;
		thermal-governor = "user_space";
		thermal-sensors = <&pm8150l_adc_tm ADC_GPIO1_PU2>;
		wake-capable-sensor;
		trips {
			active-config0 {
				temperature = <125000>;
				hysteresis = <1000>;
				type = "passive";
			};
		};
	};

	charger_therm0 {//place close to charge IC
		polling-delay-passive = <0>;
		polling-delay = <0>;
		thermal-governor = "user_space";
		thermal-sensors = <&pm8150l_adc_tm ADC_AMUX_THM3_PU2>;
		wake-capable-sensor;
		trips {
			active-config0 {
				temperature = <125000>;
				hysteresis = <1000>;
				type = "passive";
			};
		};
	};

/*	cam_therm1 {//place close to rear camera
		polling-delay-passive = <0>;
		polling-delay = <0>;
		thermal-governor = "user_space";
		thermal-sensors = <&pm8150l_adc_tm ADC_AMUX_THM1_PU2>;
		wake-capable-sensor;
		trips {
			active-config0 {
				temperature = <125000>;
				hysteresis = <1000>;
				type = "passive";
			};
		};
	};

	xo_therm {//place close to sm8250 hot place
		polling-delay-passive = <0>;
		polling-delay = <0>;
		thermal-governor = "user_space";
		thermal-sensors = <&pm8150l_adc_tm ADC_AMUX_THM2_PU2>;
		wake-capable-sensor;
		trips {
			active-config0 {
				temperature = <125000>;
				hysteresis = <1000>;
				type = "passive";
			};
		};
	};

	mmw-pa2-usr {
		polling-delay-passive = <0>;
		polling-delay = <0>;
		thermal-governor = "user_space";
		thermal-sensors = <&pm8150l_adc_tm ADC_AMUX_THM3_PU2>;
		wake-capable-sensor;
		trips {
			active-config0 {
				temperature = <125000>;
				hysteresis = <1000>;
				type = "passive";
			};
		};
	};
*/
};

&wlan {
       vdd-wlan-dig-supply = <&pm8150_s6>;
       qcom,vdd-wlan-dig-config = <950000 950000 0 0 1>;
};

&bluetooth {
        qca,bt-vdd-dig-supply = <&pm8150_s6>;
        qca,bt-vdd-dig-voltage-level = <950000 950000>;
};
